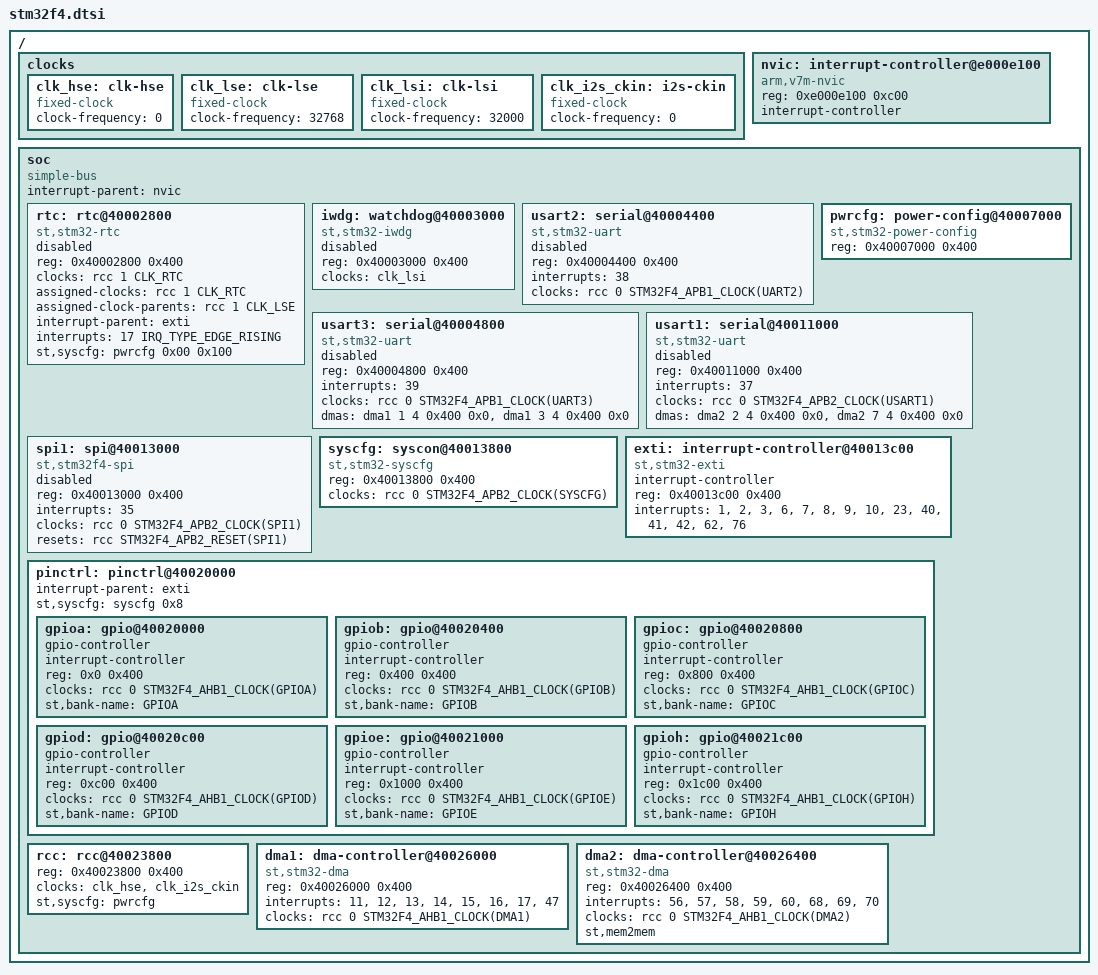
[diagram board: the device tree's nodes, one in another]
// SPDX-FileCopyrightText: 2026 Yusuf Sevim
// SPDX-License-Identifier: (GPL-2.0-only OR BSD-2-Clause)

// Blocks common to the STM32F4 parts

#include <dt-bindings/clock/stm32fx-clock.h>
#include <dt-bindings/interrupt-controller/irq.h>
#include <dt-bindings/mfd/stm32f4-rcc.h>
#include <dt-bindings/pinctrl/stm32-pinfunc.h>

/ {
	#address-cells = <1>;
	#size-cells = <1>;

	clocks {
		clk_hse: clk-hse {
			#clock-cells = <0>;
			compatible = "fixed-clock";
			clock-frequency = <0>;
		};

		clk_lse: clk-lse {
			#clock-cells = <0>;
			compatible = "fixed-clock";
			clock-frequency = <32768>;
		};

		clk_lsi: clk-lsi {
			#clock-cells = <0>;
			compatible = "fixed-clock";
			clock-frequency = <32000>;
		};

		clk_i2s_ckin: i2s-ckin {
			#clock-cells = <0>;
			compatible = "fixed-clock";
			clock-frequency = <0>;
		};
	};

	nvic: interrupt-controller@e000e100 {
		compatible = "arm,v7m-nvic";
		reg = <0xe000e100 0xc00>;
		interrupt-controller;
		#interrupt-cells = <1>;
		#address-cells = <0>;
	};

	soc {
		compatible = "simple-bus";
		#address-cells = <1>;
		#size-cells = <1>;
		interrupt-parent = <&nvic>;
		ranges;

		rtc: rtc@40002800 {
			compatible = "st,stm32-rtc";
			reg = <0x40002800 0x400>;
			clocks = <&rcc 1 CLK_RTC>;
			assigned-clocks = <&rcc 1 CLK_RTC>;
			assigned-clock-parents = <&rcc 1 CLK_LSE>;
			interrupt-parent = <&exti>;
			interrupts = <17 IRQ_TYPE_EDGE_RISING>;
			st,syscfg = <&pwrcfg 0x00 0x100>;
			status = "disabled";
		};

		iwdg: watchdog@40003000 {
			compatible = "st,stm32-iwdg";
			reg = <0x40003000 0x400>;
			clocks = <&clk_lsi>;
			clock-names = "lsi";
			status = "disabled";
		};

		usart2: serial@40004400 {
			compatible = "st,stm32-uart";
			reg = <0x40004400 0x400>;
			interrupts = <38>;
			clocks = <&rcc 0 STM32F4_APB1_CLOCK(UART2)>;
			status = "disabled";
		};

		usart3: serial@40004800 {
			compatible = "st,stm32-uart";
			reg = <0x40004800 0x400>;
			interrupts = <39>;
			clocks = <&rcc 0 STM32F4_APB1_CLOCK(UART3)>;
			status = "disabled";
			dmas = <&dma1 1 4 0x400 0x0>,
			       <&dma1 3 4 0x400 0x0>;
			dma-names = "rx", "tx";
		};

		pwrcfg: power-config@40007000 {
			compatible = "st,stm32-power-config", "syscon";
			reg = <0x40007000 0x400>;
		};

		usart1: serial@40011000 {
			compatible = "st,stm32-uart";
			reg = <0x40011000 0x400>;
			interrupts = <37>;
			clocks = <&rcc 0 STM32F4_APB2_CLOCK(USART1)>;
			status = "disabled";
			dmas = <&dma2 2 4 0x400 0x0>,
			       <&dma2 7 4 0x400 0x0>;
			dma-names = "rx", "tx";
		};

		spi1: spi@40013000 {
			#address-cells = <1>;
			#size-cells = <0>;
			compatible = "st,stm32f4-spi";
			reg = <0x40013000 0x400>;
			interrupts = <35>;
			clocks = <&rcc 0 STM32F4_APB2_CLOCK(SPI1)>;
			resets = <&rcc STM32F4_APB2_RESET(SPI1)>;
			status = "disabled";
		};

		syscfg: syscon@40013800 {
			compatible = "st,stm32-syscfg", "syscon";
			reg = <0x40013800 0x400>;
			clocks = <&rcc 0 STM32F4_APB2_CLOCK(SYSCFG)>;
		};

		// Lines 0-15: pins; 16 and up: PVD, RTC, USB wakeups
		exti: interrupt-controller@40013c00 {
			compatible = "st,stm32-exti";
			interrupt-controller;
			#interrupt-cells = <2>;
			reg = <0x40013c00 0x400>;
			interrupts = <1>, <2>, <3>, <6>, <7>, <8>, <9>, <10>, <23>, <40>, <41>, <42>,
				     <62>, <76>;
		};

		pinctrl: pinctrl@40020000 {
			#address-cells = <1>;
			#size-cells = <1>;
			ranges = <0 0x40020000 0x3000>;
			interrupt-parent = <&exti>;
			st,syscfg = <&syscfg 0x8>;

			gpioa: gpio@40020000 {
				gpio-controller;
				#gpio-cells = <2>;
				interrupt-controller;
				#interrupt-cells = <2>;
				reg = <0x0 0x400>;
				clocks = <&rcc 0 STM32F4_AHB1_CLOCK(GPIOA)>;
				st,bank-name = "GPIOA";
			};

			gpiob: gpio@40020400 {
				gpio-controller;
				#gpio-cells = <2>;
				interrupt-controller;
				#interrupt-cells = <2>;
				reg = <0x400 0x400>;
				clocks = <&rcc 0 STM32F4_AHB1_CLOCK(GPIOB)>;
				st,bank-name = "GPIOB";
			};

			gpioc: gpio@40020800 {
				gpio-controller;
				#gpio-cells = <2>;
				interrupt-controller;
				#interrupt-cells = <2>;
				reg = <0x800 0x400>;
				clocks = <&rcc 0 STM32F4_AHB1_CLOCK(GPIOC)>;
				st,bank-name = "GPIOC";
			};

			gpiod: gpio@40020c00 {
				gpio-controller;
				#gpio-cells = <2>;
				interrupt-controller;
				#interrupt-cells = <2>;
				reg = <0xc00 0x400>;
				clocks = <&rcc 0 STM32F4_AHB1_CLOCK(GPIOD)>;
				st,bank-name = "GPIOD";
			};

			gpioe: gpio@40021000 {
				gpio-controller;
				#gpio-cells = <2>;
				interrupt-controller;
				#interrupt-cells = <2>;
				reg = <0x1000 0x400>;
				clocks = <&rcc 0 STM32F4_AHB1_CLOCK(GPIOE)>;
				st,bank-name = "GPIOE";
			};

			gpioh: gpio@40021c00 {
				gpio-controller;
				#gpio-cells = <2>;
				interrupt-controller;
				#interrupt-cells = <2>;
				reg = <0x1c00 0x400>;
				clocks = <&rcc 0 STM32F4_AHB1_CLOCK(GPIOH)>;
				st,bank-name = "GPIOH";
			};
		};

		rcc: rcc@40023800 {
			#reset-cells = <1>;
			#clock-cells = <2>;
			reg = <0x40023800 0x400>;
			clocks = <&clk_hse>, <&clk_i2s_ckin>;
			st,syscfg = <&pwrcfg>;
		};

		dma1: dma-controller@40026000 {
			compatible = "st,stm32-dma";
			reg = <0x40026000 0x400>;
			interrupts = <11>, <12>, <13>, <14>, <15>, <16>, <17>, <47>;
			clocks = <&rcc 0 STM32F4_AHB1_CLOCK(DMA1)>;
			#dma-cells = <4>;
		};

		dma2: dma-controller@40026400 {
			compatible = "st,stm32-dma";
			reg = <0x40026400 0x400>;
			interrupts = <56>, <57>, <58>, <59>, <60>, <68>, <69>, <70>;
			clocks = <&rcc 0 STM32F4_AHB1_CLOCK(DMA2)>;
			#dma-cells = <4>;
			st,mem2mem;
		};
	};
};
